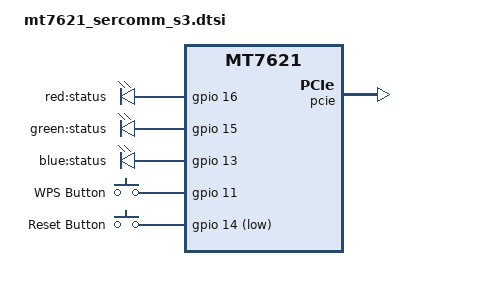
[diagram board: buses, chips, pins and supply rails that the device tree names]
// SPDX-License-Identifier: GPL-2.0-or-later OR MIT

#include "mt7621.dtsi"

#include <dt-bindings/gpio/gpio.h>
#include <dt-bindings/input/input.h>

/ {
	aliases {
		led-boot = &led_status_blue;
		led-failsafe = &led_status_red;
		led-running = &led_status_green;
		led-upgrade = &led_status_red;
	};

	leds {
		compatible = "gpio-leds";

		led_status_red: status_red {
			label = "red:status";
			gpios = <&gpio 16 GPIO_ACTIVE_HIGH>;
		};

		led_status_green: status_green {
			label = "green:status";
			gpios = <&gpio 15 GPIO_ACTIVE_HIGH>;
		};

		led_status_blue: status_blue {
			label = "blue:status";
			gpios = <&gpio 13 GPIO_ACTIVE_HIGH>;
		};
	};

	keys {
		compatible = "gpio-keys";

		wps {
			label = "WPS Button";
			gpios = <&gpio 11 GPIO_ACTIVE_HIGH>;
			linux,code = <KEY_WPS_BUTTON>;
		};

		reset {
			label = "Reset Button";
			gpios = <&gpio 14 GPIO_ACTIVE_LOW>;
			linux,code = <KEY_RESTART>;
		};
	};
};

&pcie {
	status = "okay";
};

&pcie0 {
	mt7615: mt76@0,0 {
		reg = <0x0 0 0 0 0>;
	};
};

&pcie1 {
	mt7603: mt76@0,0 {
		reg = <0x0 0 0 0 0>;
	};
};

&switch0 {
	ports {
		wan: port@0 {
			status = "okay";
			label = "wan";
		};

		port@1 {
			status = "okay";
			label = "lan1";
		};

		port@2 {
			status = "okay";
			label = "lan2";
		};

		port@3 {
			status = "okay";
			label = "lan3";
		};

		port@4 {
			status = "okay";
			label = "lan4";
		};
	};
};

&state_default {
	gpio {
		groups = "jtag", "uart2";
		function = "gpio";
	};
};
